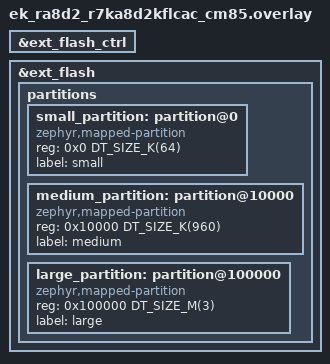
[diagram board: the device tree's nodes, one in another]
/*
 * Copyright (c) 2026 Renesas Electronics Corporation
 * SPDX-License-Identifier: Apache-2.0
 */

/delete-node/ &storage_partition;

&ext_flash_ctrl {
	status = "okay";
};

&ext_flash {
	status = "okay";

	partitions {
		ranges;
		#address-cells = <1>;
		#size-cells = <1>;

		small_partition: partition@0 {
			compatible = "zephyr,mapped-partition";
			reg = <0x0 DT_SIZE_K(64)>;
			label = "small";
		};

		medium_partition: partition@10000 {
			compatible = "zephyr,mapped-partition";
			reg = <0x10000 DT_SIZE_K(960)>;
			label = "medium";
		};

		large_partition: partition@100000 {
			compatible = "zephyr,mapped-partition";
			reg = <0x100000 DT_SIZE_M(3)>;
			label = "large";
		};
	};
};
